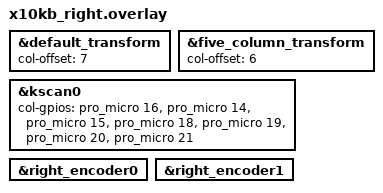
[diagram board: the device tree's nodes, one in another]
/*
 * Copyright (c) 2020 Pete Johanson
 *
 * SPDX-License-Identifier: MIT
 */

#include "x10kb.dtsi"

&default_transform {
    col-offset = <7>;
};

&five_column_transform {
    col-offset = <6>;
};

&kscan0 {
    col-gpios
        = <&pro_micro 16 GPIO_ACTIVE_HIGH>
        , <&pro_micro 14 GPIO_ACTIVE_HIGH>
        , <&pro_micro 15 GPIO_ACTIVE_HIGH>
        , <&pro_micro 18 GPIO_ACTIVE_HIGH>
        , <&pro_micro 19 GPIO_ACTIVE_HIGH>
        , <&pro_micro 20 GPIO_ACTIVE_HIGH>
        , <&pro_micro 21 GPIO_ACTIVE_HIGH>
        ;
};

&right_encoder0 {
    status = "okay";
};

&right_encoder1 {
    status = "okay";
};
